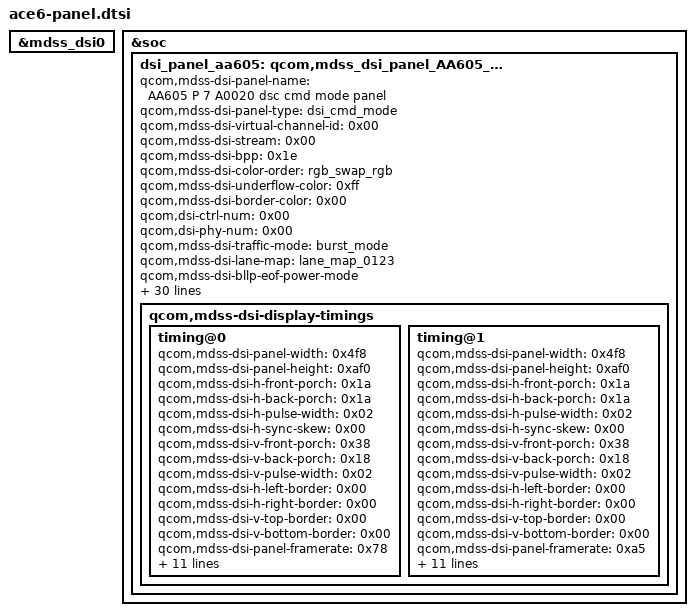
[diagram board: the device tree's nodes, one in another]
/*
 * AA605_P_7_A0020 panel, OnePlus Ace 6 (PLQ110), tianma.
 *
 * Every value below was measured from this device:
 *   dtbo_b overlay 00, node qcom,mdss_dsi_panel_AA605_P_7_A0020_dsc_cmd
 *   bootargs msm_drm.dsi_display0=<same node>:PanelID-0x009A0501:PanelSN-0x0E09170F13171008
 *
 * Timing sets present on the device: 60 / 90 / 120 / 144 / 165 Hz.
 * Only 120 Hz and 165 Hz are reproduced here; the others share the same
 * porch values and differ only in clockrate and phy-timings.
 */

&mdss_dsi0 {
    status = "okay";
};

&soc {
    dsi_panel_aa605: qcom,mdss_dsi_panel_AA605_P_7_A0020_dsc_cmd {
        qcom,mdss-dsi-panel-name = "AA605 P 7 A0020 dsc cmd mode panel";
        qcom,mdss-dsi-panel-type = "dsi_cmd_mode";
        qcom,mdss-dsi-virtual-channel-id = <0x00>;
        qcom,mdss-dsi-stream = <0x00>;
        qcom,mdss-dsi-bpp = <0x1e>;
        qcom,mdss-dsi-color-order = "rgb_swap_rgb";
        qcom,mdss-dsi-underflow-color = <0xff>;
        qcom,mdss-dsi-border-color = <0x00>;
        qcom,dsi-ctrl-num = <0x00>;
        qcom,dsi-phy-num = <0x00>;
        qcom,mdss-dsi-traffic-mode = "burst_mode";
        qcom,mdss-dsi-lane-map = "lane_map_0123";
        qcom,mdss-dsi-bllp-eof-power-mode;
        qcom,mdss-dsi-bllp-power-mode;
        qcom,mdss-dsi-lane-0-state;
        qcom,mdss-dsi-lane-1-state;
        qcom,mdss-dsi-lane-2-state;
        qcom,mdss-dsi-lane-3-state;
        qcom,mdss-dsi-dma-trigger = "trigger_sw";
        qcom,mdss-dsi-mdp-trigger = "none";
        qcom,mdss-dsi-reset-sequence = <0x01 0x02 0x00 0x05 0x01 0x19>;
        qcom,mdss-pan-physical-width-dimension = <71>;
        qcom,mdss-pan-physical-height-dimension = <157>;
        qcom,mdss-dsi-te-pin-select = <0x01>;
        qcom,mdss-dsi-te-dcs-command = <0x01>;
        qcom,mdss-dsi-te-check-enable;
        qcom,mdss-dsi-te-using-te-pin;
        qcom,mdss-dsi-wr-mem-start = <0x2c>;
        qcom,mdss-dsi-wr-mem-continue = <0x3c>;
        qcom,mdss-dsi-panel-hdr-enabled;
        qcom,mdss-dsi-panel-hdr-color-primaries = <0x3d13 0x4042 0x84d0 0x3e80 0x33c2 0x86c4 0x1d4c 0xbb8>;
        qcom,mdss-dsi-panel-peak-brightness = <0x1312d00>;
        qcom,mdss-dsi-panel-blackness-level = <0xfa0>;
        qcom,mdss-dsi-bl-pmic-control-type = "bl_ctrl_dcs";
        qcom,mdss-dsi-bl-min-level = <0x01>;
        qcom,mdss-dsi-bl-max-level = <0xffe>;
        qcom,mdss-brightness-max-level = <0xffe>;
        qcom,mdss-dsi-bl-inverted-dbv;
        qcom,platform-reset-gpio = <&tlmm 0x62 0x00>;
        qcom,platform-te-gpio = <&tlmm 0x56 0x00>;

        qcom,mdss-dsi-display-timings {
            timing@0 {
                qcom,mdss-dsi-panel-width = <0x4f8>;
                qcom,mdss-dsi-panel-height = <0xaf0>;
                qcom,mdss-dsi-h-front-porch = <0x1a>;
                qcom,mdss-dsi-h-back-porch = <0x1a>;
                qcom,mdss-dsi-h-pulse-width = <0x02>;
                qcom,mdss-dsi-h-sync-skew = <0x00>;
                qcom,mdss-dsi-v-front-porch = <0x38>;
                qcom,mdss-dsi-v-back-porch = <0x18>;
                qcom,mdss-dsi-v-pulse-width = <0x02>;
                qcom,mdss-dsi-h-left-border = <0x00>;
                qcom,mdss-dsi-h-right-border = <0x00>;
                qcom,mdss-dsi-v-top-border = <0x00>;
                qcom,mdss-dsi-v-bottom-border = <0x00>;
                qcom,mdss-dsi-panel-framerate = <0x78>;
                qcom,mdss-dsi-panel-clockrate = <0x41fb7ac0>;
                qcom,mdss-dsi-panel-phy-timings = [00 24 0a 0a 1a 18 0a 0a 09 02 04 00 1e 0f];
                qcom,mdss-dsc-version = <0x12>;
                qcom,mdss-dsc-bit-per-pixel = <0x08>;
                qcom,mdss-dsc-bit-per-component = <0x0a>;
                qcom,mdss-dsc-slice-width = <0x27c>;
                qcom,mdss-dsc-slice-height = <0x14>;
                qcom,mdss-dsc-slice-per-pkt = <0x02>;
                qcom,mdss-dsc-encoders = <0x02>;
                qcom,compression-mode = "dsc";
            };

            timing@1 {
                qcom,mdss-dsi-panel-width = <0x4f8>;
                qcom,mdss-dsi-panel-height = <0xaf0>;
                qcom,mdss-dsi-h-front-porch = <0x1a>;
                qcom,mdss-dsi-h-back-porch = <0x1a>;
                qcom,mdss-dsi-h-pulse-width = <0x02>;
                qcom,mdss-dsi-h-sync-skew = <0x00>;
                qcom,mdss-dsi-v-front-porch = <0x38>;
                qcom,mdss-dsi-v-back-porch = <0x18>;
                qcom,mdss-dsi-v-pulse-width = <0x02>;
                qcom,mdss-dsi-h-left-border = <0x00>;
                qcom,mdss-dsi-h-right-border = <0x00>;
                qcom,mdss-dsi-v-top-border = <0x00>;
                qcom,mdss-dsi-v-bottom-border = <0x00>;
                qcom,mdss-dsi-panel-framerate = <0xa5>;
                qcom,mdss-dsi-panel-clockrate = <0x5140c800>;
                qcom,mdss-dsi-panel-phy-timings = [00 2c 0c 0c 1d 1a 0c 0c 0b 02 04 00 24 11];
                qcom,mdss-dsc-version = <0x12>;
                qcom,mdss-dsc-bit-per-pixel = <0x08>;
                qcom,mdss-dsc-bit-per-component = <0x0a>;
                qcom,mdss-dsc-slice-width = <0x27c>;
                qcom,mdss-dsc-slice-height = <0x14>;
                qcom,mdss-dsc-slice-per-pkt = <0x02>;
                qcom,mdss-dsc-encoders = <0x02>;
                qcom,compression-mode = "dsc";
            };
        };
    };
};
